AUTOSAR XML (schema 4-2-2)
package /STELLANTIS/EPT/ASWCs
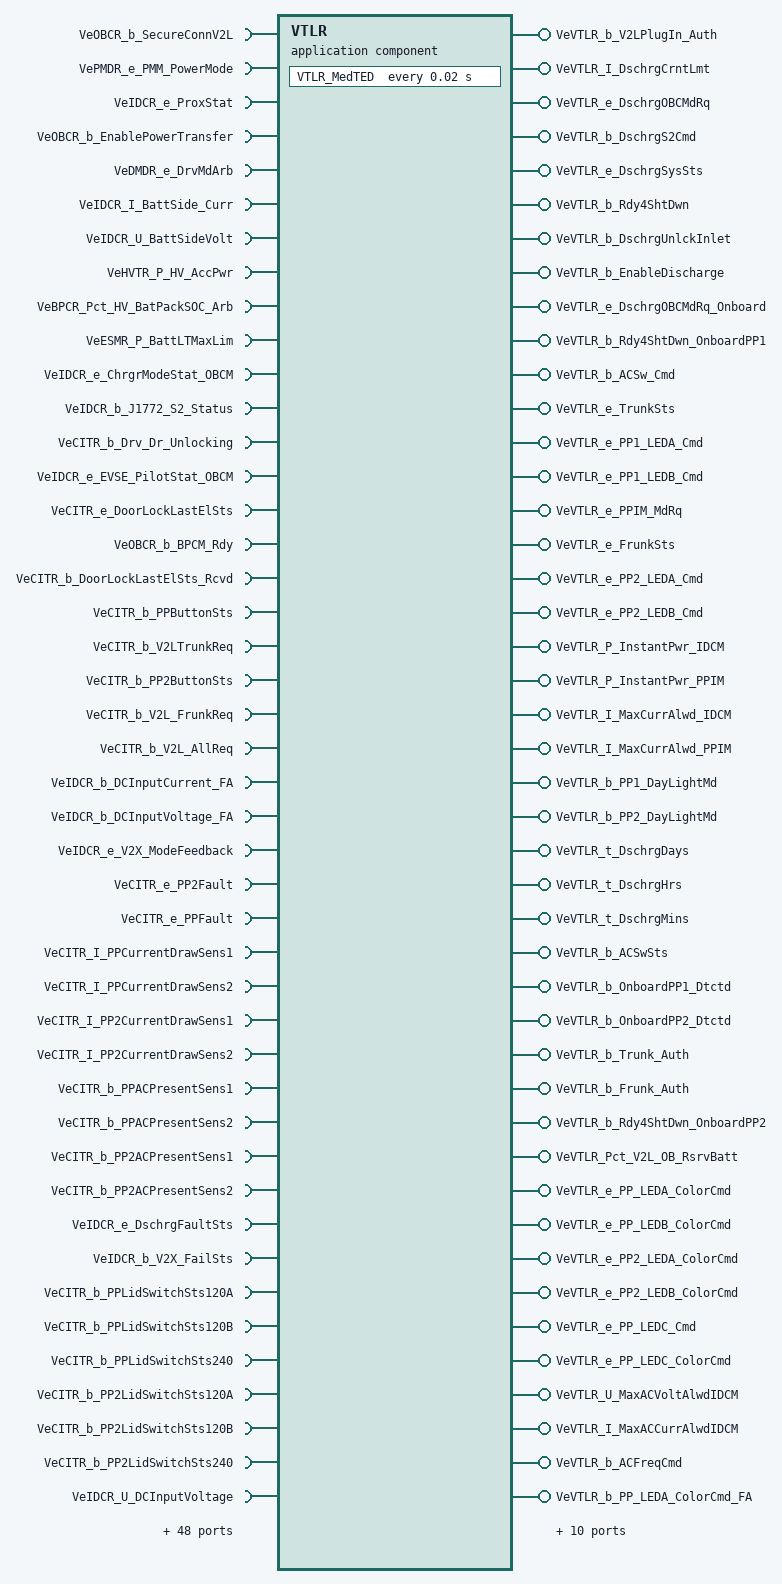
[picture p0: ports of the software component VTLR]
  application sw component type VTLR
    87 x require port:
      VeOBCR_b_SecureConnV2L: variation-point={short-label=vpVeOBCR_b_SecureConnV2L, sw-syscond=1}, nonqueued-receiver-com-spec{data-element=Value, init-value=0}, required-interface=VeOBCR_b_SecureConnV2L
      VePMDR_e_PMM_PowerMode: variation-point={short-label=vpVePMDR_e_PMM_PowerMode, sw-syscond=1}, nonqueued-receiver-com-spec{data-element=Value, init-value=CePMDR_e_PowerMode_Off}, required-interface=VePMDR_e_PMM_PowerMode
      VeIDCR_e_ProxStat: variation-point={short-label=vpVeIDCR_e_ProxStat, sw-syscond=1}, nonqueued-receiver-com-spec{data-element=Value, init-value=CeOBCR_e_ProxLo_OBCM}, required-interface=VeIDCR_e_ProxStat
      VeOBCR_b_EnablePowerTransfer: variation-point={short-label=vpVeOBCR_b_EnablePowerTransfer, sw-syscond=1}, nonqueued-receiver-com-spec{data-element=Value, init-value=0}, required-interface=VeOBCR_b_EnablePowerTransfer
      VeDMDR_e_DrvMdArb: variation-point={short-label=vpVeDMDR_e_DrvMdArb, sw-syscond=1}, nonqueued-receiver-com-spec{data-element=Value, init-value=CeDMDR_e_NoDrvMd}, required-interface=VeDMDR_e_DrvMdArb
      VeIDCR_I_BattSide_Curr: variation-point={short-label=vpVeIDCR_I_BattSide_Curr, sw-syscond=1}, nonqueued-receiver-com-spec{data-element=Value, init-value=0}, required-interface=VeIDCR_I_BattSide_Curr
      VeIDCR_U_BattSideVolt: variation-point={short-label=vpVeIDCR_U_BattSideVolt, sw-syscond=1}, nonqueued-receiver-com-spec{data-element=Value, init-value=0}, required-interface=VeIDCR_U_BattSideVolt
      VeHVTR_P_HV_AccPwr: variation-point={short-label=vpVeHVTR_P_HV_AccPwr, sw-syscond=1}, nonqueued-receiver-com-spec{data-element=Value, init-value=0}, required-interface=VeHVTR_P_HV_AccPwr
      VeBPCR_Pct_HV_BatPackSOC_Arb: variation-point={short-label=vpVeBPCR_Pct_HV_BatPackSOC_Arb, sw-syscond=1}, nonqueued-receiver-com-spec{data-element=Value, init-value=0}, required-interface=VeBPCR_Pct_HV_BatPackSOC_Arb
      VeESMR_P_BattLTMaxLim: variation-point={short-label=vpVeESMR_P_BattLTMaxLim, sw-syscond=1}, nonqueued-receiver-com-spec{data-element=Value, init-value=0}, required-interface=VeESMR_P_BattLTMaxLim
      VeIDCR_e_ChrgrModeStat_OBCM: variation-point={short-label=vpVeIDCR_e_ChrgrModeStat_OBCM, sw-syscond=1}, nonqueued-receiver-com-spec{data-element=Value, init-value=CeOBCR_e_Idle_OBCM}, required-interface=VeIDCR_e_ChrgrModeStat_OBCM
      VeIDCR_b_J1772_S2_Status: variation-point={short-label=vpVeIDCR_b_J1772_S2_Status, sw-syscond=1}, nonqueued-receiver-com-spec{data-element=Value, init-value=0}, required-interface=VeIDCR_b_J1772_S2_Status
      VeCITR_b_Drv_Dr_Unlocking: variation-point={short-label=vpVeCITR_b_Drv_Dr_Unlocking, sw-syscond=1}, nonqueued-receiver-com-spec{data-element=Value, init-value=0}, required-interface=VeCITR_b_Drv_Dr_Unlocking
      VeIDCR_e_EVSE_PilotStat_OBCM: variation-point={short-label=vpVeIDCR_e_EVSE_PilotStat_OBCM, sw-syscond=1}, nonqueued-receiver-com-spec{data-element=Value, init-value=CeOBCR_e_NO_EVSE_OBCM}, required-interface=VeIDCR_e_EVSE_PilotStat_OBCM
      VeCITR_e_DoorLockLastElSts: variation-point={short-label=vpVeCITR_e_DoorLockLastElSts, sw-syscond=1}, nonqueued-receiver-com-spec{data-element=Value, init-value=CeOBCR_e_LKD}, required-interface=VeCITR_e_DoorLockLastElSts
      VeOBCR_b_BPCM_Rdy: variation-point={short-label=vpVeOBCR_b_BPCM_Rdy, sw-syscond=1}, nonqueued-receiver-com-spec{data-element=Value, init-value=0}, required-interface=VeOBCR_b_BPCM_Rdy
      VeCITR_b_DoorLockLastElSts_Rcvd: variation-point={short-label=vpVeCITR_b_DoorLockLastElSts_Rcvd, sw-syscond=1}, nonqueued-receiver-com-spec{data-element=Value, init-value=0}, required-interface=VeCITR_b_DoorLockLastElSts_Rcvd
      VeCITR_b_PPButtonSts: variation-point={short-label=vpVeCITR_b_PPButtonSts, sw-syscond=1}, nonqueued-receiver-com-spec{data-element=Value, init-value=0}, required-interface=VeCITR_b_PPButtonSts
      VeCITR_b_V2LTrunkReq: variation-point={short-label=vpVeCITR_b_V2LTrunkReq, sw-syscond=1}, nonqueued-receiver-com-spec{data-element=Value, init-value=0}, required-interface=VeCITR_b_V2LTrunkReq
      VeCITR_b_PP2ButtonSts: variation-point={short-label=vpVeCITR_b_PP2ButtonSts, sw-syscond=1}, nonqueued-receiver-com-spec{data-element=Value, init-value=0}, required-interface=VeCITR_b_PP2ButtonSts
      VeCITR_b_V2L_FrunkReq: variation-point={short-label=vpVeCITR_b_V2L_FrunkReq, sw-syscond=1}, nonqueued-receiver-com-spec{data-element=Value, init-value=0}, required-interface=VeCITR_b_V2L_FrunkReq
      VeCITR_b_V2L_AllReq: variation-point={short-label=vpVeCITR_b_V2L_AllReq, sw-syscond=1}, nonqueued-receiver-com-spec{data-element=Value, init-value=0}, required-interface=VeCITR_b_V2L_AllReq
      VeIDCR_b_DCInputCurrent_FA: variation-point={short-label=vpVeIDCR_b_DCInputCurrent_FA, sw-syscond=1}, nonqueued-receiver-com-spec{data-element=Value, init-value=0}, required-interface=VeIDCR_b_DCInputCurrent_FA
      VeIDCR_b_DCInputVoltage_FA: variation-point={short-label=vpVeIDCR_b_DCInputVoltage_FA, sw-syscond=1}, nonqueued-receiver-com-spec{data-element=Value, init-value=0}, required-interface=VeIDCR_b_DCInputVoltage_FA
      VeIDCR_e_V2X_ModeFeedback: variation-point={short-label=vpVeIDCR_e_V2X_ModeFeedback, sw-syscond=1}, nonqueued-receiver-com-spec{data-element=Value, init-value=CeIDCR_e_No_Request}, required-interface=VeIDCR_e_V2X_ModeFeedback
      VeCITR_e_PP2Fault: variation-point={short-label=vpVeCITR_e_PP2Fault, sw-syscond=1}, nonqueued-receiver-com-spec{data-element=Value, init-value=CeVTLR_e_NoFaultPP2}, required-interface=VeCITR_e_PP2Fault
      VeCITR_e_PPFault: variation-point={short-label=vpVeCITR_e_PPFault, sw-syscond=1}, nonqueued-receiver-com-spec{data-element=Value, init-value=CeVTLR_e_NoFault}, required-interface=VeCITR_e_PPFault
      VeCITR_I_PPCurrentDrawSens1: variation-point={short-label=vpVeCITR_I_PPCurrentDrawSens1, sw-syscond=1}, nonqueued-receiver-com-spec{data-element=Value, init-value=0}, required-interface=VeCITR_I_PPCurrentDrawSens1
      VeCITR_I_PPCurrentDrawSens2: variation-point={short-label=vpVeCITR_I_PPCurrentDrawSens2, sw-syscond=1}, nonqueued-receiver-com-spec{data-element=Value, init-value=0}, required-interface=VeCITR_I_PPCurrentDrawSens2
      VeCITR_I_PP2CurrentDrawSens1: variation-point={short-label=vpVeCITR_I_PP2CurrentDrawSens1, sw-syscond=1}, nonqueued-receiver-com-spec{data-element=Value, init-value=0}, required-interface=VeCITR_I_PP2CurrentDrawSens1
      VeCITR_I_PP2CurrentDrawSens2: variation-point={short-label=vpVeCITR_I_PP2CurrentDrawSens2, sw-syscond=1}, nonqueued-receiver-com-spec{data-element=Value, init-value=0}, required-interface=VeCITR_I_PP2CurrentDrawSens2
      VeCITR_b_PPACPresentSens1: variation-point={short-label=vpVeCITR_b_PPACPresentSens1, sw-syscond=1}, nonqueued-receiver-com-spec{data-element=Value, init-value=0}, required-interface=VeCITR_b_PPACPresentSens1
      VeCITR_b_PPACPresentSens2: variation-point={short-label=vpVeCITR_b_PPACPresentSens2, sw-syscond=1}, nonqueued-receiver-com-spec{data-element=Value, init-value=0}, required-interface=VeCITR_b_PPACPresentSens2
      VeCITR_b_PP2ACPresentSens1: variation-point={short-label=vpVeCITR_b_PP2ACPresentSens1, sw-syscond=1}, nonqueued-receiver-com-spec{data-element=Value, init-value=0}, required-interface=VeCITR_b_PP2ACPresentSens1
      VeCITR_b_PP2ACPresentSens2: variation-point={short-label=vpVeCITR_b_PP2ACPresentSens2, sw-syscond=1}, nonqueued-receiver-com-spec{data-element=Value, init-value=0}, required-interface=VeCITR_b_PP2ACPresentSens2
      VeIDCR_e_DschrgFaultSts: variation-point={short-label=vpVeIDCR_e_DschrgFaultSts, sw-syscond=1}, nonqueued-receiver-com-spec{data-element=Value, init-value=CeVTLR_e_No_Fault}, required-interface=VeIDCR_e_DschrgFaultSts
      VeIDCR_b_V2X_FailSts: variation-point={short-label=vpVeIDCR_b_V2X_FailSts, sw-syscond=1}, nonqueued-receiver-com-spec{data-element=Value, init-value=0}, required-interface=VeIDCR_b_V2X_FailSts
      VeCITR_b_PPLidSwitchSts120A: variation-point={short-label=vpVeCITR_b_PPLidSwitchSts120A, sw-syscond=1}, nonqueued-receiver-com-spec{data-element=Value, init-value=0}, required-interface=VeCITR_b_PPLidSwitchSts120A
      VeCITR_b_PPLidSwitchSts120B: variation-point={short-label=vpVeCITR_b_PPLidSwitchSts120B, sw-syscond=1}, nonqueued-receiver-com-spec{data-element=Value, init-value=0}, required-interface=VeCITR_b_PPLidSwitchSts120B
      VeCITR_b_PPLidSwitchSts240: variation-point={short-label=vpVeCITR_b_PPLidSwitchSts240, sw-syscond=1}, nonqueued-receiver-com-spec{data-element=Value, init-value=0}, required-interface=VeCITR_b_PPLidSwitchSts240
      VeCITR_b_PP2LidSwitchSts120A: variation-point={short-label=vpVeCITR_b_PP2LidSwitchSts120A, sw-syscond=1}, nonqueued-receiver-com-spec{data-element=Value, init-value=0}, required-interface=VeCITR_b_PP2LidSwitchSts120A
      VeCITR_b_PP2LidSwitchSts120B: variation-point={short-label=vpVeCITR_b_PP2LidSwitchSts120B, sw-syscond=1}, nonqueued-receiver-com-spec{data-element=Value, init-value=0}, required-interface=VeCITR_b_PP2LidSwitchSts120B
      VeCITR_b_PP2LidSwitchSts240: variation-point={short-label=vpVeCITR_b_PP2LidSwitchSts240, sw-syscond=1}, nonqueued-receiver-com-spec{data-element=Value, init-value=0}, required-interface=VeCITR_b_PP2LidSwitchSts240
      VeIDCR_U_DCInputVoltage: variation-point={short-label=vpVeIDCR_U_DCInputVoltage, sw-syscond=1}, nonqueued-receiver-com-spec{data-element=Value, init-value=0}, required-interface=VeIDCR_U_DCInputVoltage
      VeIDCR_b_DschrgFaultSts_FA: variation-point={short-label=vpVeIDCR_b_DschrgFaultSts_FA, sw-syscond=1}, nonqueued-receiver-com-spec{data-element=Value, init-value=0}, required-interface=VeIDCR_b_DschrgFaultSts_FA
      VeIDCR_b_V2X_InputCurrent_FA: variation-point={short-label=vpVeIDCR_b_V2X_InputCurrent_FA, sw-syscond=1}, nonqueued-receiver-com-spec{data-element=Value, init-value=0}, required-interface=VeIDCR_b_V2X_InputCurrent_FA
      VeIDCR_b_V2X_InputVoltage_FA: variation-point={short-label=vpVeIDCR_b_V2X_InputVoltage_FA, sw-syscond=1}, nonqueued-receiver-com-spec{data-element=Value, init-value=0}, required-interface=VeIDCR_b_V2X_InputVoltage_FA
      VeIDCR_b_V2X_FailSts_FA: variation-point={short-label=vpVeIDCR_b_V2X_FailSts_FA, sw-syscond=1}, nonqueued-receiver-com-spec{data-element=Value, init-value=0}, required-interface=VeIDCR_b_V2X_FailSts_FA
      VeCITR_P_PPRatedPower: variation-point={short-label=vpVeCITR_P_PPRatedPower, sw-syscond=1}, nonqueued-receiver-com-spec{data-element=Value, init-value=0}, required-interface=VeCITR_P_PPRatedPower
      VeCITR_P_PP2RatedPower: variation-point={short-label=vpVeCITR_P_PP2RatedPower, sw-syscond=1}, nonqueued-receiver-com-spec{data-element=Value, init-value=0}, required-interface=VeCITR_P_PP2RatedPower
      VeIDCR_U_V2X_InputVoltage: variation-point={short-label=vpVeIDCR_U_V2X_InputVoltage, sw-syscond=1}, nonqueued-receiver-com-spec{data-element=Value, init-value=0}, required-interface=VeIDCR_U_V2X_InputVoltage
      VePLTR_t_RTC_CurrentTime: variation-point={short-label=vpVePLTR_t_RTC_CurrentTime, sw-syscond=1}, nonqueued-receiver-com-spec{data-element=Value, init-value=0}, required-interface=VePLTR_t_RTC_CurrentTime
      VeIDCR_I_ACOutCurrent1: variation-point={short-label=vpVeIDCR_I_ACOutCurrent1, sw-syscond=1}, nonqueued-receiver-com-spec{data-element=Value, init-value=0}, required-interface=VeIDCR_I_ACOutCurrent1
      VeIDCR_U_ACOutVoltage1: variation-point={short-label=vpVeIDCR_U_ACOutVoltage1, sw-syscond=1}, nonqueued-receiver-com-spec{data-element=Value, init-value=0}, required-interface=VeIDCR_U_ACOutVoltage1
      VeIDCR_I_ACOutCurrent2: variation-point={short-label=vpVeIDCR_I_ACOutCurrent2, sw-syscond=1}, nonqueued-receiver-com-spec{data-element=Value, init-value=0}, required-interface=VeIDCR_I_ACOutCurrent2
      VeIDCR_U_ACOutVoltage2: variation-point={short-label=vpVeIDCR_U_ACOutVoltage2, sw-syscond=1}, nonqueued-receiver-com-spec{data-element=Value, init-value=0}, required-interface=VeIDCR_U_ACOutVoltage2
      VeIDCR_I_AcOutCurrent: variation-point={short-label=vpVeIDCR_I_AcOutCurrent, sw-syscond=1}, nonqueued-receiver-com-spec{data-element=Value, init-value=0}, required-interface=VeIDCR_I_AcOutCurrent
      VeIDCR_U_AcOutVoltage: variation-point={short-label=vpVeIDCR_U_AcOutVoltage, sw-syscond=1}, nonqueued-receiver-com-spec{data-element=Value, init-value=0}, required-interface=VeIDCR_U_AcOutVoltage
      VeERER_E_WhRemaining_V2L: variation-point={short-label=vpVeERER_E_WhRemaining_V2L, sw-syscond=1}, nonqueued-receiver-com-spec{data-element=Value, init-value=0}, required-interface=VeERER_E_WhRemaining_V2L
      VeVTXR_e_PowerPanelMd: variation-point={short-label=vpVeVTXR_e_PowerPanelMd, sw-syscond=1}, nonqueued-receiver-com-spec{data-element=Value, init-value=CeVTXR_e_DefaultMd}, required-interface=VeVTXR_e_PowerPanelMd
      VeHPMR_b_PropSysActv: variation-point={short-label=vpVeHPMR_b_PropSysActv, sw-syscond=1}, nonqueued-receiver-com-spec{data-element=Value, init-value=0}, required-interface=VeHPMR_b_PropSysActv
      VeCITR_b_V2LSubmit: variation-point={short-label=vpVeCITR_b_V2LSubmit, sw-syscond=1}, nonqueued-receiver-com-spec{data-element=Value, init-value=0}, required-interface=VeCITR_b_V2LSubmit
      VeVDVR_e_DschrgSysSts: variation-point={short-label=vpVeVDVR_e_DschrgSysSts, sw-syscond=1}, nonqueued-receiver-com-spec{data-element=Value, init-value=CeVTLR_e_DschrgInactv}, required-interface=VeVDVR_e_DschrgSysSts
      VeVDVR_I_DschrgCrntLmt: variation-point={short-label=vpVeVDVR_I_DschrgCrntLmt, sw-syscond=1}, nonqueued-receiver-com-spec{data-element=Value, init-value=0}, required-interface=VeVDVR_I_DschrgCrntLmt
      VeSSDR_b_DsblHVBattDischrg: variation-point={short-label=vpVeSSDR_b_DsblHVBattDischrg, sw-syscond=1}, nonqueued-receiver-com-spec{data-element=Value, init-value=0}, required-interface=VeSSDR_b_DsblHVBattDischrg
      VeSRAR_b_StpCharging: variation-point={short-label=vpVeSRAR_b_StpCharging, sw-syscond=1}, nonqueued-receiver-com-spec{data-element=Value, init-value=0}, required-interface=VeSRAR_b_StpCharging
      VeGENR_b_LV_SysVoltage_Low: variation-point={short-label=vpVeGENR_b_LV_SysVoltage_Low, sw-syscond=1}, nonqueued-receiver-com-spec{data-element=Value, init-value=0}, required-interface=VeGENR_b_LV_SysVoltage_Low
      VeCITR_e_FOTA_Install_Type: variation-point={short-label=vpVeCITR_e_FOTA_Install_Type, sw-syscond=1}, nonqueued-receiver-com-spec{data-element=Value, init-value=CeCITR_e_NoFOTA}, required-interface=VeCITR_e_FOTA_Install_Type
      VeCITR_e_FOTA_Install_Status: variation-point={short-label=vpVeCITR_e_FOTA_Install_Status, sw-syscond=1}, nonqueued-receiver-com-spec{data-element=Value, init-value=CeCITR_e_Installation_Default}, required-interface=VeCITR_e_FOTA_Install_Status
      VeFSCR_b_HVFuncRejHdAjar: variation-point={short-label=vpVeFSCR_b_HVFuncRejHdAjar, sw-syscond=1}, nonqueued-receiver-com-spec{data-element=Value, init-value=0}, required-interface=VeFSCR_b_HVFuncRejHdAjar
      VeBPCR_e_HV_BatCntctrStat: variation-point={short-label=vpVeBPCR_e_HV_BatCntctrStat, sw-syscond=1}, nonqueued-receiver-com-spec{data-element=Value, init-value=CeHVTR_e_Open}, required-interface=VeBPCR_e_HV_BatCntctrStat
      VeCSVR_v_VehSpdSigned: variation-point={short-label=vpVeCSVR_v_VehSpdSigned, sw-syscond=1}, nonqueued-receiver-com-spec{data-element=Value, init-value=0}, required-interface=VeCSVR_v_VehSpdSigned
      VeCSVR_b_VehSpdFA: variation-point={short-label=vpVeCSVR_b_VehSpdFA, sw-syscond=1}, nonqueued-receiver-com-spec{data-element=Value, init-value=0}, required-interface=VeCSVR_b_VehSpdFA
      VeHPMR_b_BattCntctrOpenPndg: variation-point={short-label=vpVeHPMR_b_BattCntctrOpenPndg, sw-syscond=1}, nonqueued-receiver-com-spec{data-element=Value, init-value=0}, required-interface=VeHPMR_b_BattCntctrOpenPndg
      VePLTR_b_RmtVehStartReq: variation-point={short-label=vpVePLTR_b_RmtVehStartReq, sw-syscond=1}, nonqueued-receiver-com-spec{data-element=Value, init-value=0}, required-interface=VePLTR_b_RmtVehStartReq
      VeOBCR_b_PluggedIn: variation-point={short-label=vpVeOBCR_b_PluggedIn, sw-syscond=1}, nonqueued-receiver-com-spec{data-element=Value, init-value=0}, required-interface=VeOBCR_b_PluggedIn
      VePLTR_b_InternalLightSts: variation-point={short-label=vpVePLTR_b_InternalLightSts, sw-syscond=1}, nonqueued-receiver-com-spec{data-element=Value, init-value=0}, required-interface=VePLTR_b_InternalLightSts
      VeDMDR_e_TurtleMdSts: variation-point={short-label=vpVeDMDR_e_TurtleMdSts, sw-syscond=1}, nonqueued-receiver-com-spec{data-element=Value, init-value=CeDMDR_e_No_Turtle_Mode}, required-interface=VeDMDR_e_TurtleMdSts
      VeHPMR_b_CntrlrPwrHold: variation-point={short-label=vpVeHPMR_b_CntrlrPwrHold, sw-syscond=1}, nonqueued-receiver-com-spec{data-element=Value, init-value=0}, required-interface=VeHPMR_b_CntrlrPwrHold
      VeTRGR_e_VldtdTransRngSt: variation-point={short-label=vpVeTRGR_e_VldtdTransRngSt, sw-syscond=1}, nonqueued-receiver-com-spec{data-element=Value, init-value=CeTRGR_e_NoSelectionAvailable}, required-interface=VeTRGR_e_VldtdTransRngSt
      VePRXR_e_OnboardPowPanelType: variation-point={short-label=vpVePRXR_e_OnboardPowPanelType, sw-syscond=1}, nonqueued-receiver-com-spec{data-element=Value, init-value=CePRXR_e_NoType}, required-interface=VePRXR_e_OnboardPowPanelType
      VePRXR_b_V2L_Present: variation-point={short-label=vpVePRXR_b_V2L_Present, sw-syscond=1}, nonqueued-receiver-com-spec{data-element=Value, init-value=0}, required-interface=VePRXR_b_V2L_Present
      VeCITR_b_PP_Gnd_Fault_Detected: variation-point={short-label=vpVeCITR_b_PP_Gnd_Fault_Detected, sw-syscond=1}, nonqueued-receiver-com-spec{data-element=Value, init-value=0}, required-interface=VeCITR_b_PP_Gnd_Fault_Detected
      VeCITR_b_PP2_Gnd_Fault_Detected: variation-point={short-label=vpVeCITR_b_PP2_Gnd_Fault_Detected, sw-syscond=1}, nonqueued-receiver-com-spec{data-element=Value, init-value=0}, required-interface=VeCITR_b_PP2_Gnd_Fault_Detected
      VeIDCR_b_IDCM_GFCI_Fault_Status: variation-point={short-label=vpVeIDCR_b_IDCM_GFCI_Fault_Status, sw-syscond=1}, nonqueued-receiver-com-spec{data-element=Value, init-value=0}, required-interface=VeIDCR_b_IDCM_GFCI_Fault_Status
      VeIDCR_I_DCInputCurrent: variation-point={short-label=vpVeIDCR_I_DCInputCurrent, sw-syscond=1}, nonqueued-receiver-com-spec{data-element=Value, init-value=0}, required-interface=VeIDCR_I_DCInputCurrent
      VeIDCR_I_V2X_InputCurrent: variation-point={short-label=vpVeIDCR_I_V2X_InputCurrent, sw-syscond=1}, nonqueued-receiver-com-spec{data-element=Value, init-value=0}, required-interface=VeIDCR_I_V2X_InputCurrent
    49 x provide port:
      VeVTLR_b_V2LPlugIn_Auth: nonqueued-sender-com-spec{data-element=Value, init-value=0}, provided-interface=VeVTLR_b_V2LPlugIn_Auth
      VeVTLR_I_DschrgCrntLmt: nonqueued-sender-com-spec{data-element=Value, init-value=0}, provided-interface=VeVTLR_I_DschrgCrntLmt
      VeVTLR_e_DschrgOBCMdRq: nonqueued-sender-com-spec{data-element=Value, init-value=CeOBCR_e_Idle_OBCMdRq}, provided-interface=VeVTLR_e_DschrgOBCMdRq
      VeVTLR_b_DschrgS2Cmd: nonqueued-sender-com-spec{data-element=Value, init-value=0}, provided-interface=VeVTLR_b_DschrgS2Cmd
      VeVTLR_e_DschrgSysSts: nonqueued-sender-com-spec{data-element=Value, init-value=CeVTLR_e_DschrgInactv}, provided-interface=VeVTLR_e_DschrgSysSts
      VeVTLR_b_Rdy4ShtDwn: nonqueued-sender-com-spec{data-element=Value, init-value=0}, provided-interface=VeVTLR_b_Rdy4ShtDwn
      VeVTLR_b_DschrgUnlckInlet: nonqueued-sender-com-spec{data-element=Value, init-value=0}, provided-interface=VeVTLR_b_DschrgUnlckInlet
      VeVTLR_b_EnableDischarge: nonqueued-sender-com-spec{data-element=Value, init-value=0}, provided-interface=VeVTLR_b_EnableDischarge
      VeVTLR_e_DschrgOBCMdRq_Onboard: nonqueued-sender-com-spec{data-element=Value, init-value=CeOBCR_e_Idle_OBCMdRq}, provided-interface=VeVTLR_e_DschrgOBCMdRq_Onboard
      VeVTLR_b_Rdy4ShtDwn_OnboardPP1: nonqueued-sender-com-spec{data-element=Value, init-value=0}, provided-interface=VeVTLR_b_Rdy4ShtDwn_OnboardPP1
      VeVTLR_b_ACSw_Cmd: nonqueued-sender-com-spec{data-element=Value, init-value=0}, provided-interface=VeVTLR_b_ACSw_Cmd
      VeVTLR_e_TrunkSts: nonqueued-sender-com-spec{data-element=Value, init-value=CeVTLR_e_Inactive}, provided-interface=VeVTLR_e_TrunkSts
      VeVTLR_e_PP1_LEDA_Cmd: nonqueued-sender-com-spec{data-element=Value, init-value=CeVTLR_e_Led_Off}, provided-interface=VeVTLR_e_PP1_LEDA_Cmd
      VeVTLR_e_PP1_LEDB_Cmd: nonqueued-sender-com-spec{data-element=Value, init-value=CeVTLR_e_Led_Off}, provided-interface=VeVTLR_e_PP1_LEDB_Cmd
      VeVTLR_e_PPIM_MdRq: nonqueued-sender-com-spec{data-element=Value, init-value=CeVTLR_e_Idle}, provided-interface=VeVTLR_e_PPIM_MdRq
      VeVTLR_e_FrunkSts: nonqueued-sender-com-spec{data-element=Value, init-value=CeVTLR_e_Inactive_Frunk}, provided-interface=VeVTLR_e_FrunkSts
      VeVTLR_e_PP2_LEDA_Cmd: nonqueued-sender-com-spec{data-element=Value, init-value=CeVTLR_e_Led_Off}, provided-interface=VeVTLR_e_PP2_LEDA_Cmd
      VeVTLR_e_PP2_LEDB_Cmd: nonqueued-sender-com-spec{data-element=Value, init-value=CeVTLR_e_Led_Off}, provided-interface=VeVTLR_e_PP2_LEDB_Cmd
      VeVTLR_P_InstantPwr_IDCM: nonqueued-sender-com-spec{data-element=Value, init-value=0}, provided-interface=VeVTLR_P_InstantPwr_IDCM
      VeVTLR_P_InstantPwr_PPIM: nonqueued-sender-com-spec{data-element=Value, init-value=0}, provided-interface=VeVTLR_P_InstantPwr_PPIM
      VeVTLR_I_MaxCurrAlwd_IDCM: nonqueued-sender-com-spec{data-element=Value, init-value=0}, provided-interface=VeVTLR_I_MaxCurrAlwd_IDCM
      VeVTLR_I_MaxCurrAlwd_PPIM: nonqueued-sender-com-spec{data-element=Value, init-value=0}, provided-interface=VeVTLR_I_MaxCurrAlwd_PPIM
      VeVTLR_b_PP1_DayLightMd: nonqueued-sender-com-spec{data-element=Value, init-value=0}, provided-interface=VeVTLR_b_PP1_DayLightMd
      VeVTLR_b_PP2_DayLightMd: nonqueued-sender-com-spec{data-element=Value, init-value=0}, provided-interface=VeVTLR_b_PP2_DayLightMd
      VeVTLR_t_DschrgDays: nonqueued-sender-com-spec{data-element=Value, init-value=0}, provided-interface=VeVTLR_t_DschrgDays
      VeVTLR_t_DschrgHrs: nonqueued-sender-com-spec{data-element=Value, init-value=0}, provided-interface=VeVTLR_t_DschrgHrs
      VeVTLR_t_DschrgMins: nonqueued-sender-com-spec{data-element=Value, init-value=0}, provided-interface=VeVTLR_t_DschrgMins
      VeVTLR_b_ACSwSts: nonqueued-sender-com-spec{data-element=Value, init-value=0}, provided-interface=VeVTLR_b_ACSwSts
      VeVTLR_b_OnboardPP1_Dtctd: nonqueued-sender-com-spec{data-element=Value, init-value=0}, provided-interface=VeVTLR_b_OnboardPP1_Dtctd
      VeVTLR_b_OnboardPP2_Dtctd: nonqueued-sender-com-spec{data-element=Value, init-value=0}, provided-interface=VeVTLR_b_OnboardPP2_Dtctd
      VeVTLR_b_Trunk_Auth: nonqueued-sender-com-spec{data-element=Value, init-value=0}, provided-interface=VeVTLR_b_Trunk_Auth
      VeVTLR_b_Frunk_Auth: nonqueued-sender-com-spec{data-element=Value, init-value=0}, provided-interface=VeVTLR_b_Frunk_Auth
      VeVTLR_b_Rdy4ShtDwn_OnboardPP2: nonqueued-sender-com-spec{data-element=Value, init-value=0}, provided-interface=VeVTLR_b_Rdy4ShtDwn_OnboardPP2
      VeVTLR_Pct_V2L_OB_RsrvBatt: nonqueued-sender-com-spec{data-element=Value, init-value=0}, provided-interface=VeVTLR_Pct_V2L_OB_RsrvBatt
      VeVTLR_e_PP_LEDA_ColorCmd: nonqueued-sender-com-spec{data-element=Value, init-value=CeVTLR_e_Init}, provided-interface=VeVTLR_e_PP_LEDA_ColorCmd
      VeVTLR_e_PP_LEDB_ColorCmd: nonqueued-sender-com-spec{data-element=Value, init-value=CeVTLR_e_Init}, provided-interface=VeVTLR_e_PP_LEDB_ColorCmd
      VeVTLR_e_PP2_LEDA_ColorCmd: nonqueued-sender-com-spec{data-element=Value, init-value=CeVTLR_e_Init}, provided-interface=VeVTLR_e_PP2_LEDA_ColorCmd
      VeVTLR_e_PP2_LEDB_ColorCmd: nonqueued-sender-com-spec{data-element=Value, init-value=CeVTLR_e_Init}, provided-interface=VeVTLR_e_PP2_LEDB_ColorCmd
      VeVTLR_e_PP_LEDC_Cmd: nonqueued-sender-com-spec{data-element=Value, init-value=CeVTLR_e_Led_Off}, provided-interface=VeVTLR_e_PP_LEDC_Cmd
      VeVTLR_e_PP_LEDC_ColorCmd: nonqueued-sender-com-spec{data-element=Value, init-value=CeVTLR_e_Init}, provided-interface=VeVTLR_e_PP_LEDC_ColorCmd
      VeVTLR_U_MaxACVoltAlwdIDCM: nonqueued-sender-com-spec{data-element=Value, init-value=0}, provided-interface=VeVTLR_U_MaxACVoltAlwdIDCM
      VeVTLR_I_MaxACCurrAlwdIDCM: nonqueued-sender-com-spec{data-element=Value, init-value=0}, provided-interface=VeVTLR_I_MaxACCurrAlwdIDCM
      VeVTLR_b_ACFreqCmd: nonqueued-sender-com-spec{data-element=Value, init-value=0}, provided-interface=VeVTLR_b_ACFreqCmd
      VeVTLR_b_PP_LEDA_ColorCmd_FA: nonqueued-sender-com-spec{data-element=Value, init-value=0}, provided-interface=VeVTLR_b_PP_LEDA_ColorCmd_FA
      VeVTLR_b_PP_LEDB_ColorCmd_FA: nonqueued-sender-com-spec{data-element=Value, init-value=0}, provided-interface=VeVTLR_b_PP_LEDB_ColorCmd_FA
      VeVTLR_b_PP_LEDC_ColorCmd_FA: nonqueued-sender-com-spec{data-element=Value, init-value=0}, provided-interface=VeVTLR_b_PP_LEDC_ColorCmd_FA
      VeVTLR_b_PP2_LEDA_ColorCmd_FA: nonqueued-sender-com-spec{data-element=Value, init-value=0}, provided-interface=VeVTLR_b_PP2_LEDA_ColorCmd_FA
      VeVTLR_b_PP2_LEDB_ColorCmd_FA: nonqueued-sender-com-spec{data-element=Value, init-value=0}, provided-interface=VeVTLR_b_PP2_LEDB_ColorCmd_FA
      VeVTLR_b_PP_LEDC_Cmd_FA: nonqueued-sender-com-spec{data-element=Value, init-value=0}, provided-interface=VeVTLR_b_PP_LEDC_Cmd_FA
    5 x require port:
      EeVTLR_b_V2L_PlugInAuth_Rx: variation-point={short-label=vpEeVTLR_b_V2L_PlugInAuth_Rx, sw-syscond=1}, nv-require-com-spec{init-value=0, variable=EeVTLR_b_V2L_PlugInAuth}, required-interface=EeVTLR_b_V2L_PlugInAuth
      EeVTLR_Cnt_AuthTmr_Rx: variation-point={short-label=vpEeVTLR_Cnt_AuthTmr_Rx, sw-syscond=1}, nv-require-com-spec{init-value=0, variable=EeVTLR_Cnt_AuthTmr}, required-interface=EeVTLR_Cnt_AuthTmr
      NeVTLR_e_DoorLastSts_Rx: variation-point={short-label=vpNeVTLR_e_DoorLastSts_Rx, sw-syscond=1}, nv-require-com-spec{init-value=CeOBCR_e_LKD, variable=NeVTLR_e_DoorLastSts}, required-interface=NeVTLR_e_DoorLastSts
      EeVTLR_b_V2L_OB_IDCM_Auth_Rx: variation-point={short-label=vpEeVTLR_b_V2L_OB_IDCM_Auth_Rx, sw-syscond=1}, nv-require-com-spec{init-value=0, variable=EeVTLR_b_V2L_OB_IDCM_Auth}, required-interface=EeVTLR_b_V2L_OB_IDCM_Auth
      EeVTLR_b_V2L_OB_PPIM_Auth_Rx: variation-point={short-label=vpEeVTLR_b_V2L_OB_PPIM_Auth_Rx, sw-syscond=1}, nv-require-com-spec{init-value=0, variable=EeVTLR_b_V2L_OB_PPIM_Auth}, required-interface=EeVTLR_b_V2L_OB_PPIM_Auth
    5 x provide port:
      EeVTLR_b_V2L_PlugInAuth: variation-point={short-label=vpEeVTLR_b_V2L_PlugInAuth, sw-syscond=1}, nv-provide-com-spec{ram-block-init-value=0, variable=EeVTLR_b_V2L_PlugInAuth}, provided-interface=EeVTLR_b_V2L_PlugInAuth
      EeVTLR_Cnt_AuthTmr: variation-point={short-label=vpEeVTLR_Cnt_AuthTmr, sw-syscond=1}, nv-provide-com-spec{ram-block-init-value=0, variable=EeVTLR_Cnt_AuthTmr}, provided-interface=EeVTLR_Cnt_AuthTmr
      NeVTLR_e_DoorLastSts: variation-point={short-label=vpNeVTLR_e_DoorLastSts, sw-syscond=1}, nv-provide-com-spec{ram-block-init-value=CeOBCR_e_LKD, variable=NeVTLR_e_DoorLastSts}, provided-interface=NeVTLR_e_DoorLastSts
      EeVTLR_b_V2L_OB_IDCM_Auth: variation-point={short-label=vpEeVTLR_b_V2L_OB_IDCM_Auth, sw-syscond=1}, nv-provide-com-spec{ram-block-init-value=0, variable=EeVTLR_b_V2L_OB_IDCM_Auth}, provided-interface=EeVTLR_b_V2L_OB_IDCM_Auth
      EeVTLR_b_V2L_OB_PPIM_Auth: variation-point={short-label=vpEeVTLR_b_V2L_OB_PPIM_Auth, sw-syscond=1}, nv-provide-com-spec{ram-block-init-value=0, variable=EeVTLR_b_V2L_OB_PPIM_Auth}, provided-interface=EeVTLR_b_V2L_OB_PPIM_Auth
    behavior IB_VTLR: data-type-mapping=msADTtoIDTMapping, handle-termination-and-restart=NO-SUPPORT, included-data-type-set=data-type=TeVTLR_e_DischrgSt
      timing event Event_MedTED: start-on-event=VTLR_MedTED, period=0.02
      init event Event_VTLR_ac_Init: start-on-event=VTLR_ac_Init
      init event Event_PwrOn: start-on-event=VTLR_PwrOn
      init event Event_PwrOff: start-on-event=VTLR_PwrOff
      4 x runnable:
        VTLR_ac_Init
          data-send-points:
            16 x access:
              OUT_VeVTLR_e_DschrgOBCMdRq_Value: accessed-variable=VeVTLR_e_DschrgOBCMdRq.Value
              OUT_VeVTLR_e_DschrgSysSts_Value: accessed-variable=VeVTLR_e_DschrgSysSts.Value
              OUT_VeVTLR_e_DschrgOBCMdRq_Onboard_Value: accessed-variable=VeVTLR_e_DschrgOBCMdRq_Onboard.Value
              OUT_VeVTLR_e_TrunkSts_Value: accessed-variable=VeVTLR_e_TrunkSts.Value
              OUT_VeVTLR_e_PP1_LEDA_Cmd_Value: accessed-variable=VeVTLR_e_PP1_LEDA_Cmd.Value
              OUT_VeVTLR_e_PP1_LEDB_Cmd_Value: accessed-variable=VeVTLR_e_PP1_LEDB_Cmd.Value
              OUT_VeVTLR_e_PPIM_MdRq_Value: accessed-variable=VeVTLR_e_PPIM_MdRq.Value
              OUT_VeVTLR_e_FrunkSts_Value: accessed-variable=VeVTLR_e_FrunkSts.Value
              OUT_VeVTLR_e_PP2_LEDA_Cmd_Value: accessed-variable=VeVTLR_e_PP2_LEDA_Cmd.Value
              OUT_VeVTLR_e_PP2_LEDB_Cmd_Value: accessed-variable=VeVTLR_e_PP2_LEDB_Cmd.Value
              OUT_VeVTLR_e_PP_LEDA_ColorCmd_Value: accessed-variable=VeVTLR_e_PP_LEDA_ColorCmd.Value
              OUT_VeVTLR_e_PP_LEDB_ColorCmd_Value: accessed-variable=VeVTLR_e_PP_LEDB_ColorCmd.Value
              OUT_VeVTLR_e_PP2_LEDA_ColorCmd_Value: accessed-variable=VeVTLR_e_PP2_LEDA_ColorCmd.Value
              OUT_VeVTLR_e_PP2_LEDB_ColorCmd_Value: accessed-variable=VeVTLR_e_PP2_LEDB_ColorCmd.Value
              OUT_VeVTLR_e_PP_LEDC_Cmd_Value: accessed-variable=VeVTLR_e_PP_LEDC_Cmd.Value
              OUT_VeVTLR_e_PP_LEDC_ColorCmd_Value: accessed-variable=VeVTLR_e_PP_LEDC_ColorCmd.Value
        VTLR_PwrOn
          data-receive-point-by-arguments:
            5 x access:
              IN_EeVTLR_Cnt_AuthTmr_Rx_EeVTLR_Cnt_AuthTmr: accessed-variable=EeVTLR_Cnt_AuthTmr_Rx.EeVTLR_Cnt_AuthTmr, variation-point={short-label=vpIN_EeVTLR_Cnt_AuthTmr_Rx_EeVTLR_Cnt_AuthTmr, sw-syscond=1}
              IN_EeVTLR_b_V2L_OB_IDCM_Auth_Rx_EeVTLR_b_V2L_OB_IDCM_Auth: accessed-variable=EeVTLR_b_V2L_OB_IDCM_Auth_Rx.EeVTLR_b_V2L_OB_IDCM_Auth, variation-point={short-label=vpIN_EeVTLR_b_V2L_OB_IDCM_Auth_Rx_EeVTLR_b_V2L_OB_IDCM_Auth, sw-syscond=1}
              IN_EeVTLR_b_V2L_OB_PPIM_Auth_Rx_EeVTLR_b_V2L_OB_PPIM_Auth: accessed-variable=EeVTLR_b_V2L_OB_PPIM_Auth_Rx.EeVTLR_b_V2L_OB_PPIM_Auth, variation-point={short-label=vpIN_EeVTLR_b_V2L_OB_PPIM_Auth_Rx_EeVTLR_b_V2L_OB_PPIM_Auth, sw-syscond=1}
              IN_EeVTLR_b_V2L_PlugInAuth_Rx_EeVTLR_b_V2L_PlugInAuth: accessed-variable=EeVTLR_b_V2L_PlugInAuth_Rx.EeVTLR_b_V2L_PlugInAuth, variation-point={short-label=vpIN_EeVTLR_b_V2L_PlugInAuth_Rx_EeVTLR_b_V2L_PlugInAuth, sw-syscond=1}
              IN_NeVTLR_e_DoorLastSts_Rx_NeVTLR_e_DoorLastSts: accessed-variable=NeVTLR_e_DoorLastSts_Rx.NeVTLR_e_DoorLastSts, variation-point={short-label=vpIN_NeVTLR_e_DoorLastSts_Rx_NeVTLR_e_DoorLastSts, sw-syscond=1}
          data-send-points:
            49 x access:
              OUT_VeVTLR_b_V2LPlugIn_Auth_Value: accessed-variable=VeVTLR_b_V2LPlugIn_Auth.Value
              OUT_VeVTLR_I_DschrgCrntLmt_Value: accessed-variable=VeVTLR_I_DschrgCrntLmt.Value
              OUT_VeVTLR_e_DschrgOBCMdRq_Value: accessed-variable=VeVTLR_e_DschrgOBCMdRq.Value
              OUT_VeVTLR_b_DschrgS2Cmd_Value: accessed-variable=VeVTLR_b_DschrgS2Cmd.Value
              OUT_VeVTLR_e_DschrgSysSts_Value: accessed-variable=VeVTLR_e_DschrgSysSts.Value
              OUT_VeVTLR_b_Rdy4ShtDwn_Value: accessed-variable=VeVTLR_b_Rdy4ShtDwn.Value
              OUT_VeVTLR_b_DschrgUnlckInlet_Value: accessed-variable=VeVTLR_b_DschrgUnlckInlet.Value
              OUT_VeVTLR_b_EnableDischarge_Value: accessed-variable=VeVTLR_b_EnableDischarge.Value
              OUT_VeVTLR_e_DschrgOBCMdRq_Onboard_Value: accessed-variable=VeVTLR_e_DschrgOBCMdRq_Onboard.Value
              OUT_VeVTLR_b_Rdy4ShtDwn_OnboardPP1_Value: accessed-variable=VeVTLR_b_Rdy4ShtDwn_OnboardPP1.Value
              OUT_VeVTLR_b_Rdy4ShtDwn_OnboardPP2_Value: accessed-variable=VeVTLR_b_Rdy4ShtDwn_OnboardPP2.Value
              OUT_VeVTLR_b_ACSw_Cmd_Value: accessed-variable=VeVTLR_b_ACSw_Cmd.Value
              OUT_VeVTLR_e_TrunkSts_Value: accessed-variable=VeVTLR_e_TrunkSts.Value
              OUT_VeVTLR_e_PP1_LEDA_Cmd_Value: accessed-variable=VeVTLR_e_PP1_LEDA_Cmd.Value
              OUT_VeVTLR_e_PP1_LEDB_Cmd_Value: accessed-variable=VeVTLR_e_PP1_LEDB_Cmd.Value
              OUT_VeVTLR_e_PPIM_MdRq_Value: accessed-variable=VeVTLR_e_PPIM_MdRq.Value
              OUT_VeVTLR_e_FrunkSts_Value: accessed-variable=VeVTLR_e_FrunkSts.Value
              OUT_VeVTLR_e_PP2_LEDA_Cmd_Value: accessed-variable=VeVTLR_e_PP2_LEDA_Cmd.Value
              OUT_VeVTLR_e_PP2_LEDB_Cmd_Value: accessed-variable=VeVTLR_e_PP2_LEDB_Cmd.Value
              OUT_VeVTLR_P_InstantPwr_IDCM_Value: accessed-variable=VeVTLR_P_InstantPwr_IDCM.Value
              OUT_VeVTLR_P_InstantPwr_PPIM_Value: accessed-variable=VeVTLR_P_InstantPwr_PPIM.Value
              OUT_VeVTLR_I_MaxCurrAlwd_IDCM_Value: accessed-variable=VeVTLR_I_MaxCurrAlwd_IDCM.Value
              OUT_VeVTLR_I_MaxCurrAlwd_PPIM_Value: accessed-variable=VeVTLR_I_MaxCurrAlwd_PPIM.Value
              OUT_VeVTLR_b_PP1_DayLightMd_Value: accessed-variable=VeVTLR_b_PP1_DayLightMd.Value
              OUT_VeVTLR_b_PP2_DayLightMd_Value: accessed-variable=VeVTLR_b_PP2_DayLightMd.Value
              OUT_VeVTLR_t_DschrgDays_Value: accessed-variable=VeVTLR_t_DschrgDays.Value
              OUT_VeVTLR_t_DschrgHrs_Value: accessed-variable=VeVTLR_t_DschrgHrs.Value
              OUT_VeVTLR_t_DschrgMins_Value: accessed-variable=VeVTLR_t_DschrgMins.Value
              OUT_VeVTLR_b_ACSwSts_Value: accessed-variable=VeVTLR_b_ACSwSts.Value
              OUT_VeVTLR_b_OnboardPP1_Dtctd_Value: accessed-variable=VeVTLR_b_OnboardPP1_Dtctd.Value
              OUT_VeVTLR_b_OnboardPP2_Dtctd_Value: accessed-variable=VeVTLR_b_OnboardPP2_Dtctd.Value
              OUT_VeVTLR_b_Trunk_Auth_Value: accessed-variable=VeVTLR_b_Trunk_Auth.Value
              OUT_VeVTLR_b_Frunk_Auth_Value: accessed-variable=VeVTLR_b_Frunk_Auth.Value
              OUT_VeVTLR_Pct_V2L_OB_RsrvBatt_Value: accessed-variable=VeVTLR_Pct_V2L_OB_RsrvBatt.Value
              OUT_VeVTLR_e_PP_LEDA_ColorCmd_Value: accessed-variable=VeVTLR_e_PP_LEDA_ColorCmd.Value
              OUT_VeVTLR_e_PP_LEDB_ColorCmd_Value: accessed-variable=VeVTLR_e_PP_LEDB_ColorCmd.Value
              OUT_VeVTLR_e_PP2_LEDA_ColorCmd_Value: accessed-variable=VeVTLR_e_PP2_LEDA_ColorCmd.Value
              OUT_VeVTLR_e_PP2_LEDB_ColorCmd_Value: accessed-variable=VeVTLR_e_PP2_LEDB_ColorCmd.Value
              OUT_VeVTLR_e_PP_LEDC_Cmd_Value: accessed-variable=VeVTLR_e_PP_LEDC_Cmd.Value
              OUT_VeVTLR_e_PP_LEDC_ColorCmd_Value: accessed-variable=VeVTLR_e_PP_LEDC_ColorCmd.Value
              OUT_VeVTLR_U_MaxACVoltAlwdIDCM_Value: accessed-variable=VeVTLR_U_MaxACVoltAlwdIDCM.Value
              OUT_VeVTLR_I_MaxACCurrAlwdIDCM_Value: accessed-variable=VeVTLR_I_MaxACCurrAlwdIDCM.Value
              OUT_VeVTLR_b_ACFreqCmd_Value: accessed-variable=VeVTLR_b_ACFreqCmd.Value
              OUT_VeVTLR_b_PP_LEDA_ColorCmd_FA_Value: accessed-variable=VeVTLR_b_PP_LEDA_ColorCmd_FA.Value
              OUT_VeVTLR_b_PP_LEDB_ColorCmd_FA_Value: accessed-variable=VeVTLR_b_PP_LEDB_ColorCmd_FA.Value
              OUT_VeVTLR_b_PP_LEDC_Cmd_FA_Value: accessed-variable=VeVTLR_b_PP_LEDC_Cmd_FA.Value
              OUT_VeVTLR_b_PP_LEDC_ColorCmd_FA_Value: accessed-variable=VeVTLR_b_PP_LEDC_ColorCmd_FA.Value
              OUT_VeVTLR_b_PP2_LEDA_ColorCmd_FA_Value: accessed-variable=VeVTLR_b_PP2_LEDA_ColorCmd_FA.Value
              OUT_VeVTLR_b_PP2_LEDB_ColorCmd_FA_Value: accessed-variable=VeVTLR_b_PP2_LEDB_ColorCmd_FA.Value
        VTLR_MedTED: variation-point={short-label=vpVTLR_MedTED, sw-syscond=1}
          data-receive-point-by-arguments:
            71 x access:
              IN_VeBPCR_Pct_HV_BatPackSOC_Arb_Value: accessed-variable=VeBPCR_Pct_HV_BatPackSOC_Arb.Value, variation-point={short-label=vpIN_VeBPCR_Pct_HV_BatPackSOC_Arb_Value, sw-syscond=1}
              IN_VeBPCR_e_HV_BatCntctrStat_Value: accessed-variable=VeBPCR_e_HV_BatCntctrStat.Value, variation-point={short-label=vpIN_VeBPCR_e_HV_BatCntctrStat_Value, sw-syscond=1}
              IN_VeCITR_I_PP2CurrentDrawSens1_Value: accessed-variable=VeCITR_I_PP2CurrentDrawSens1.Value, variation-point={short-label=vpIN_VeCITR_I_PP2CurrentDrawSens1_Value, sw-syscond=1}
              IN_VeCITR_I_PP2CurrentDrawSens2_Value: accessed-variable=VeCITR_I_PP2CurrentDrawSens2.Value, variation-point={short-label=vpIN_VeCITR_I_PP2CurrentDrawSens2_Value, sw-syscond=1}
              IN_VeCITR_I_PPCurrentDrawSens1_Value: accessed-variable=VeCITR_I_PPCurrentDrawSens1.Value, variation-point={short-label=vpIN_VeCITR_I_PPCurrentDrawSens1_Value, sw-syscond=1}
              IN_VeCITR_I_PPCurrentDrawSens2_Value: accessed-variable=VeCITR_I_PPCurrentDrawSens2.Value, variation-point={short-label=vpIN_VeCITR_I_PPCurrentDrawSens2_Value, sw-syscond=1}
              IN_VeCITR_P_PP2RatedPower_Value: accessed-variable=VeCITR_P_PP2RatedPower.Value, variation-point={short-label=vpIN_VeCITR_P_PP2RatedPower_Value, sw-syscond=1}
              IN_VeCITR_P_PPRatedPower_Value: accessed-variable=VeCITR_P_PPRatedPower.Value, variation-point={short-label=vpIN_VeCITR_P_PPRatedPower_Value, sw-syscond=1}
              IN_VeCITR_b_DoorLockLastElSts_Rcvd_Value: accessed-variable=VeCITR_b_DoorLockLastElSts_Rcvd.Value, variation-point={short-label=vpIN_VeCITR_b_DoorLockLastElSts_Rcvd_Value, sw-syscond=1}
              IN_VeCITR_b_Drv_Dr_Unlocking_Value: accessed-variable=VeCITR_b_Drv_Dr_Unlocking.Value, variation-point={short-label=vpIN_VeCITR_b_Drv_Dr_Unlocking_Value, sw-syscond=1}
              IN_VeCITR_b_PP2ACPresentSens1_Value: accessed-variable=VeCITR_b_PP2ACPresentSens1.Value, variation-point={short-label=vpIN_VeCITR_b_PP2ACPresentSens1_Value, sw-syscond=1}
              IN_VeCITR_b_PP2ACPresentSens2_Value: accessed-variable=VeCITR_b_PP2ACPresentSens2.Value, variation-point={short-label=vpIN_VeCITR_b_PP2ACPresentSens2_Value, sw-syscond=1}
              IN_VeCITR_b_PP2ButtonSts_Value: accessed-variable=VeCITR_b_PP2ButtonSts.Value, variation-point={short-label=vpIN_VeCITR_b_PP2ButtonSts_Value, sw-syscond=1}
              IN_VeCITR_b_PP2LidSwitchSts120A_Value: accessed-variable=VeCITR_b_PP2LidSwitchSts120A.Value, variation-point={short-label=vpIN_VeCITR_b_PP2LidSwitchSts120A_Value, sw-syscond=1}
              IN_VeCITR_b_PP2LidSwitchSts120B_Value: accessed-variable=VeCITR_b_PP2LidSwitchSts120B.Value, variation-point={short-label=vpIN_VeCITR_b_PP2LidSwitchSts120B_Value, sw-syscond=1}
              IN_VeCITR_b_PP2LidSwitchSts240_Value: accessed-variable=VeCITR_b_PP2LidSwitchSts240.Value, variation-point={short-label=vpIN_VeCITR_b_PP2LidSwitchSts240_Value, sw-syscond=1}
              IN_VeCITR_b_PPACPresentSens1_Value: accessed-variable=VeCITR_b_PPACPresentSens1.Value, variation-point={short-label=vpIN_VeCITR_b_PPACPresentSens1_Value, sw-syscond=1}
              IN_VeCITR_b_PPACPresentSens2_Value: accessed-variable=VeCITR_b_PPACPresentSens2.Value, variation-point={short-label=vpIN_VeCITR_b_PPACPresentSens2_Value, sw-syscond=1}
              IN_VeCITR_b_PPButtonSts_Value: accessed-variable=VeCITR_b_PPButtonSts.Value, variation-point={short-label=vpIN_VeCITR_b_PPButtonSts_Value, sw-syscond=1}
              IN_VeCITR_b_PPLidSwitchSts120A_Value: accessed-variable=VeCITR_b_PPLidSwitchSts120A.Value, variation-point={short-label=vpIN_VeCITR_b_PPLidSwitchSts120A_Value, sw-syscond=1}
              IN_VeCITR_b_PPLidSwitchSts120B_Value: accessed-variable=VeCITR_b_PPLidSwitchSts120B.Value, variation-point={short-label=vpIN_VeCITR_b_PPLidSwitchSts120B_Value, sw-syscond=1}
              IN_VeCITR_b_PPLidSwitchSts240_Value: accessed-variable=VeCITR_b_PPLidSwitchSts240.Value, variation-point={short-label=vpIN_VeCITR_b_PPLidSwitchSts240_Value, sw-syscond=1}
              IN_VeCITR_b_V2LSubmit_Value: accessed-variable=VeCITR_b_V2LSubmit.Value, variation-point={short-label=vpIN_VeCITR_b_V2LSubmit_Value, sw-syscond=1}
              IN_VeCITR_b_V2LTrunkReq_Value: accessed-variable=VeCITR_b_V2LTrunkReq.Value, variation-point={short-label=vpIN_VeCITR_b_V2LTrunkReq_Value, sw-syscond=1}
              IN_VeCITR_b_V2L_AllReq_Value: accessed-variable=VeCITR_b_V2L_AllReq.Value, variation-point={short-label=vpIN_VeCITR_b_V2L_AllReq_Value, sw-syscond=1}
              IN_VeCITR_b_V2L_FrunkReq_Value: accessed-variable=VeCITR_b_V2L_FrunkReq.Value, variation-point={short-label=vpIN_VeCITR_b_V2L_FrunkReq_Value, sw-syscond=1}
              IN_VeCITR_e_DoorLockLastElSts_Value: accessed-variable=VeCITR_e_DoorLockLastElSts.Value, variation-point={short-label=vpIN_VeCITR_e_DoorLockLastElSts_Value, sw-syscond=1}
              IN_VeCITR_e_FOTA_Install_Status_Value: accessed-variable=VeCITR_e_FOTA_Install_Status.Value, variation-point={short-label=vpIN_VeCITR_e_FOTA_Install_Status_Value, sw-syscond=1}
              IN_VeCITR_e_FOTA_Install_Type_Value: accessed-variable=VeCITR_e_FOTA_Install_Type.Value, variation-point={short-label=vpIN_VeCITR_e_FOTA_Install_Type_Value, sw-syscond=1}
              IN_VeCITR_e_PP2Fault_Value: accessed-variable=VeCITR_e_PP2Fault.Value, variation-point={short-label=vpIN_VeCITR_e_PP2Fault_Value, sw-syscond=1}
              IN_VeCITR_e_PPFault_Value: accessed-variable=VeCITR_e_PPFault.Value, variation-point={short-label=vpIN_VeCITR_e_PPFault_Value, sw-syscond=1}
              IN_VeCSVR_b_VehSpdFA_Value: accessed-variable=VeCSVR_b_VehSpdFA.Value, variation-point={short-label=vpIN_VeCSVR_b_VehSpdFA_Value, sw-syscond=1}
              IN_VeCSVR_v_VehSpdSigned_Value: accessed-variable=VeCSVR_v_VehSpdSigned.Value, variation-point={short-label=vpIN_VeCSVR_v_VehSpdSigned_Value, sw-syscond=1}
              IN_VeDMDR_e_DrvMdArb_Value: accessed-variable=VeDMDR_e_DrvMdArb.Value, variation-point={short-label=vpIN_VeDMDR_e_DrvMdArb_Value, sw-syscond=1}
              IN_VeDMDR_e_TurtleMdSts_Value: accessed-variable=VeDMDR_e_TurtleMdSts.Value, variation-point={short-label=vpIN_VeDMDR_e_TurtleMdSts_Value, sw-syscond=1}
              IN_VeERER_E_WhRemaining_V2L_Value: accessed-variable=VeERER_E_WhRemaining_V2L.Value, variation-point={short-label=vpIN_VeERER_E_WhRemaining_V2L_Value, sw-syscond=1}
              IN_VeESMR_P_BattLTMaxLim_Value: accessed-variable=VeESMR_P_BattLTMaxLim.Value, variation-point={short-label=vpIN_VeESMR_P_BattLTMaxLim_Value, sw-syscond=1}
              IN_VeFSCR_b_HVFuncRejHdAjar_Value: accessed-variable=VeFSCR_b_HVFuncRejHdAjar.Value, variation-point={short-label=vpIN_VeFSCR_b_HVFuncRejHdAjar_Value, sw-syscond=1}
              IN_VeGENR_b_LV_SysVoltage_Low_Value: accessed-variable=VeGENR_b_LV_SysVoltage_Low.Value, variation-point={short-label=vpIN_VeGENR_b_LV_SysVoltage_Low_Value, sw-syscond=1}
              IN_VeHPMR_b_BattCntctrOpenPndg_Value: accessed-variable=VeHPMR_b_BattCntctrOpenPndg.Value, variation-point={short-label=vpIN_VeHPMR_b_BattCntctrOpenPndg_Value, sw-syscond=1}
              IN_VeHPMR_b_CntrlrPwrHold_Value: accessed-variable=VeHPMR_b_CntrlrPwrHold.Value, variation-point={short-label=vpIN_VeHPMR_b_CntrlrPwrHold_Value, sw-syscond=1}
              IN_VeHPMR_b_PropSysActv_Value: accessed-variable=VeHPMR_b_PropSysActv.Value, variation-point={short-label=vpIN_VeHPMR_b_PropSysActv_Value, sw-syscond=1}
              IN_VeHVTR_P_HV_AccPwr_Value: accessed-variable=VeHVTR_P_HV_AccPwr.Value, variation-point={short-label=vpIN_VeHVTR_P_HV_AccPwr_Value, sw-syscond=1}
              IN_VeIDCR_I_BattSide_Curr_Value: accessed-variable=VeIDCR_I_BattSide_Curr.Value, variation-point={short-label=vpIN_VeIDCR_I_BattSide_Curr_Value, sw-syscond=1}
              IN_VeIDCR_I_DCInputCurrent_Value: accessed-variable=VeIDCR_I_DCInputCurrent.Value, variation-point={short-label=vpIN_VeIDCR_I_DCInputCurrent_Value, sw-syscond=1}
              IN_VeIDCR_I_V2X_InputCurrent_Value: accessed-variable=VeIDCR_I_V2X_InputCurrent.Value, variation-point={short-label=vpIN_VeIDCR_I_V2X_InputCurrent_Value, sw-syscond=1}
              IN_VeIDCR_U_ACOutVoltage1_Value: accessed-variable=VeIDCR_U_ACOutVoltage1.Value, variation-point={short-label=vpIN_VeIDCR_U_ACOutVoltage1_Value, sw-syscond=1}
              IN_VeIDCR_U_BattSideVolt_Value: accessed-variable=VeIDCR_U_BattSideVolt.Value, variation-point={short-label=vpIN_VeIDCR_U_BattSideVolt_Value, sw-syscond=1}
              IN_VeIDCR_U_DCInputVoltage_Value: accessed-variable=VeIDCR_U_DCInputVoltage.Value, variation-point={short-label=vpIN_VeIDCR_U_DCInputVoltage_Value, sw-syscond=1}
              IN_VeIDCR_U_V2X_InputVoltage_Value: accessed-variable=VeIDCR_U_V2X_InputVoltage.Value, variation-point={short-label=vpIN_VeIDCR_U_V2X_InputVoltage_Value, sw-syscond=1}
              IN_VeIDCR_b_J1772_S2_Status_Value: accessed-variable=VeIDCR_b_J1772_S2_Status.Value, variation-point={short-label=vpIN_VeIDCR_b_J1772_S2_Status_Value, sw-syscond=1}
              IN_VeIDCR_b_V2X_FailSts_Value: accessed-variable=VeIDCR_b_V2X_FailSts.Value, variation-point={short-label=vpIN_VeIDCR_b_V2X_FailSts_Value, sw-syscond=1}
              IN_VeIDCR_e_ChrgrModeStat_OBCM_Value: accessed-variable=VeIDCR_e_ChrgrModeStat_OBCM.Value, variation-point={short-label=vpIN_VeIDCR_e_ChrgrModeStat_OBCM_Value, sw-syscond=1}
              IN_VeIDCR_e_DschrgFaultSts_Value: accessed-variable=VeIDCR_e_DschrgFaultSts.Value, variation-point={short-label=vpIN_VeIDCR_e_DschrgFaultSts_Value, sw-syscond=1}
              IN_VeIDCR_e_EVSE_PilotStat_OBCM_Value: accessed-variable=VeIDCR_e_EVSE_PilotStat_OBCM.Value, variation-point={short-label=vpIN_VeIDCR_e_EVSE_PilotStat_OBCM_Value, sw-syscond=1}
              IN_VeIDCR_e_ProxStat_Value: accessed-variable=VeIDCR_e_ProxStat.Value, variation-point={short-label=vpIN_VeIDCR_e_ProxStat_Value, sw-syscond=1}
              IN_VeIDCR_e_V2X_ModeFeedback_Value: accessed-variable=VeIDCR_e_V2X_ModeFeedback.Value, variation-point={short-label=vpIN_VeIDCR_e_V2X_ModeFeedback_Value, sw-syscond=1}
              IN_VeOBCR_b_BPCM_Rdy_Value: accessed-variable=VeOBCR_b_BPCM_Rdy.Value, variation-point={short-label=vpIN_VeOBCR_b_BPCM_Rdy_Value, sw-syscond=1}
              IN_VeOBCR_b_EnablePowerTransfer_Value: accessed-variable=VeOBCR_b_EnablePowerTransfer.Value, variation-point={short-label=vpIN_VeOBCR_b_EnablePowerTransfer_Value, sw-syscond=1}
              IN_VeOBCR_b_PluggedIn_Value: accessed-variable=VeOBCR_b_PluggedIn.Value, variation-point={short-label=vpIN_VeOBCR_b_PluggedIn_Value, sw-syscond=1}
              IN_VeOBCR_b_SecureConnV2L_Value: accessed-variable=VeOBCR_b_SecureConnV2L.Value, variation-point={short-label=vpIN_VeOBCR_b_SecureConnV2L_Value, sw-syscond=1}
              IN_VePLTR_b_InternalLightSts_Value: accessed-variable=VePLTR_b_InternalLightSts.Value, variation-point={short-label=vpIN_VePLTR_b_InternalLightSts_Value, sw-syscond=1}
              IN_VePLTR_b_RmtVehStartReq_Value: accessed-variable=VePLTR_b_RmtVehStartReq.Value, variation-point={short-label=vpIN_VePLTR_b_RmtVehStartReq_Value, sw-syscond=1}
              IN_VePLTR_t_RTC_CurrentTime_Value: accessed-variable=VePLTR_t_RTC_CurrentTime.Value, variation-point={short-label=vpIN_VePLTR_t_RTC_CurrentTime_Value, sw-syscond=1}
              IN_VePMDR_e_PMM_PowerMode_Value: accessed-variable=VePMDR_e_PMM_PowerMode.Value, variation-point={short-label=vpIN_VePMDR_e_PMM_PowerMode_Value, sw-syscond=1}
              IN_VeSRAR_b_StpCharging_Value: accessed-variable=VeSRAR_b_StpCharging.Value, variation-point={short-label=vpIN_VeSRAR_b_StpCharging_Value, sw-syscond=1}
              IN_VeSSDR_b_DsblHVBattDischrg_Value: accessed-variable=VeSSDR_b_DsblHVBattDischrg.Value, variation-point={short-label=vpIN_VeSSDR_b_DsblHVBattDischrg_Value, sw-syscond=1}
              IN_VeTRGR_e_VldtdTransRngSt_Value: accessed-variable=VeTRGR_e_VldtdTransRngSt.Value, variation-point={short-label=vpIN_VeTRGR_e_VldtdTransRngSt_Value, sw-syscond=1}
              IN_VeVDVR_I_DschrgCrntLmt_Value: accessed-variable=VeVDVR_I_DschrgCrntLmt.Value, variation-point={short-label=vpIN_VeVDVR_I_DschrgCrntLmt_Value, sw-syscond=1}
              IN_VeVDVR_e_DschrgSysSts_Value: accessed-variable=VeVDVR_e_DschrgSysSts.Value, variation-point={short-label=vpIN_VeVDVR_e_DschrgSysSts_Value, sw-syscond=1}
              IN_VeVTXR_e_PowerPanelMd_Value: accessed-variable=VeVTXR_e_PowerPanelMd.Value, variation-point={short-label=vpIN_VeVTXR_e_PowerPanelMd_Value, sw-syscond=1}
          data-send-points:
            49 x access:
              OUT_VeVTLR_b_V2LPlugIn_Auth_Value: accessed-variable=VeVTLR_b_V2LPlugIn_Auth.Value
              OUT_VeVTLR_I_DschrgCrntLmt_Value: accessed-variable=VeVTLR_I_DschrgCrntLmt.Value
              OUT_VeVTLR_e_DschrgOBCMdRq_Value: accessed-variable=VeVTLR_e_DschrgOBCMdRq.Value
              OUT_VeVTLR_b_DschrgS2Cmd_Value: accessed-variable=VeVTLR_b_DschrgS2Cmd.Value
              OUT_VeVTLR_b_DschrgUnlckInlet_Value: accessed-variable=VeVTLR_b_DschrgUnlckInlet.Value
              OUT_VeVTLR_b_EnableDischarge_Value: accessed-variable=VeVTLR_b_EnableDischarge.Value
              OUT_VeVTLR_b_Trunk_Auth_Value: accessed-variable=VeVTLR_b_Trunk_Auth.Value
              OUT_VeVTLR_b_Frunk_Auth_Value: accessed-variable=VeVTLR_b_Frunk_Auth.Value
              OUT_VeVTLR_e_DschrgOBCMdRq_Onboard_Value: accessed-variable=VeVTLR_e_DschrgOBCMdRq_Onboard.Value
              OUT_VeVTLR_b_ACSw_Cmd_Value: accessed-variable=VeVTLR_b_ACSw_Cmd.Value
              OUT_VeVTLR_e_TrunkSts_Value: accessed-variable=VeVTLR_e_TrunkSts.Value
              OUT_VeVTLR_e_PP1_LEDA_Cmd_Value: accessed-variable=VeVTLR_e_PP1_LEDA_Cmd.Value
              OUT_VeVTLR_e_PP1_LEDB_Cmd_Value: accessed-variable=VeVTLR_e_PP1_LEDB_Cmd.Value
              OUT_VeVTLR_e_PPIM_MdRq_Value: accessed-variable=VeVTLR_e_PPIM_MdRq.Value
              OUT_VeVTLR_b_Rdy4ShtDwn_Value: accessed-variable=VeVTLR_b_Rdy4ShtDwn.Value
              OUT_VeVTLR_e_FrunkSts_Value: accessed-variable=VeVTLR_e_FrunkSts.Value
              OUT_VeVTLR_e_PP2_LEDA_Cmd_Value: accessed-variable=VeVTLR_e_PP2_LEDA_Cmd.Value
              OUT_VeVTLR_e_PP2_LEDB_Cmd_Value: accessed-variable=VeVTLR_e_PP2_LEDB_Cmd.Value
              OUT_VeVTLR_P_InstantPwr_IDCM_Value: accessed-variable=VeVTLR_P_InstantPwr_IDCM.Value
              OUT_VeVTLR_P_InstantPwr_PPIM_Value: accessed-variable=VeVTLR_P_InstantPwr_PPIM.Value
              OUT_VeVTLR_I_MaxCurrAlwd_PPIM_Value: accessed-variable=VeVTLR_I_MaxCurrAlwd_PPIM.Value
              OUT_VeVTLR_b_PP1_DayLightMd_Value: accessed-variable=VeVTLR_b_PP1_DayLightMd.Value
              OUT_VeVTLR_b_PP2_DayLightMd_Value: accessed-variable=VeVTLR_b_PP2_DayLightMd.Value
              OUT_VeVTLR_t_DschrgDays_Value: accessed-variable=VeVTLR_t_DschrgDays.Value
              OUT_VeVTLR_t_DschrgHrs_Value: accessed-variable=VeVTLR_t_DschrgHrs.Value
              OUT_VeVTLR_t_DschrgMins_Value: accessed-variable=VeVTLR_t_DschrgMins.Value
              OUT_VeVTLR_b_OnboardPP1_Dtctd_Value: accessed-variable=VeVTLR_b_OnboardPP1_Dtctd.Value
              OUT_VeVTLR_b_OnboardPP2_Dtctd_Value: accessed-variable=VeVTLR_b_OnboardPP2_Dtctd.Value
              OUT_VeVTLR_b_Rdy4ShtDwn_OnboardPP1_Value: accessed-variable=VeVTLR_b_Rdy4ShtDwn_OnboardPP1.Value
              OUT_VeVTLR_b_Rdy4ShtDwn_OnboardPP2_Value: accessed-variable=VeVTLR_b_Rdy4ShtDwn_OnboardPP2.Value
              OUT_VeVTLR_b_ACSwSts_Value: accessed-variable=VeVTLR_b_ACSwSts.Value
              OUT_VeVTLR_I_MaxCurrAlwd_IDCM_Value: accessed-variable=VeVTLR_I_MaxCurrAlwd_IDCM.Value
              OUT_VeVTLR_e_DschrgSysSts_Value: accessed-variable=VeVTLR_e_DschrgSysSts.Value
              OUT_VeVTLR_Pct_V2L_OB_RsrvBatt_Value: accessed-variable=VeVTLR_Pct_V2L_OB_RsrvBatt.Value
              OUT_VeVTLR_e_PP_LEDA_ColorCmd_Value: accessed-variable=VeVTLR_e_PP_LEDA_ColorCmd.Value
              OUT_VeVTLR_e_PP_LEDB_ColorCmd_Value: accessed-variable=VeVTLR_e_PP_LEDB_ColorCmd.Value
              OUT_VeVTLR_e_PP2_LEDA_ColorCmd_Value: accessed-variable=VeVTLR_e_PP2_LEDA_ColorCmd.Value
              OUT_VeVTLR_e_PP2_LEDB_ColorCmd_Value: accessed-variable=VeVTLR_e_PP2_LEDB_ColorCmd.Value
              OUT_VeVTLR_e_PP_LEDC_Cmd_Value: accessed-variable=VeVTLR_e_PP_LEDC_Cmd.Value
              OUT_VeVTLR_e_PP_LEDC_ColorCmd_Value: accessed-variable=VeVTLR_e_PP_LEDC_ColorCmd.Value
              OUT_VeVTLR_U_MaxACVoltAlwdIDCM_Value: accessed-variable=VeVTLR_U_MaxACVoltAlwdIDCM.Value
              OUT_VeVTLR_I_MaxACCurrAlwdIDCM_Value: accessed-variable=VeVTLR_I_MaxACCurrAlwdIDCM.Value
              OUT_VeVTLR_b_ACFreqCmd_Value: accessed-variable=VeVTLR_b_ACFreqCmd.Value
              OUT_VeVTLR_b_PP_LEDA_ColorCmd_FA_Value: accessed-variable=VeVTLR_b_PP_LEDA_ColorCmd_FA.Value
              OUT_VeVTLR_b_PP_LEDB_ColorCmd_FA_Value: accessed-variable=VeVTLR_b_PP_LEDB_ColorCmd_FA.Value
              OUT_VeVTLR_b_PP_LEDC_ColorCmd_FA_Value: accessed-variable=VeVTLR_b_PP_LEDC_ColorCmd_FA.Value
              OUT_VeVTLR_b_PP2_LEDA_ColorCmd_FA_Value: accessed-variable=VeVTLR_b_PP2_LEDA_ColorCmd_FA.Value
              OUT_VeVTLR_b_PP2_LEDB_ColorCmd_FA_Value: accessed-variable=VeVTLR_b_PP2_LEDB_ColorCmd_FA.Value
              OUT_VeVTLR_b_PP_LEDC_Cmd_FA_Value: accessed-variable=VeVTLR_b_PP_LEDC_Cmd_FA.Value
        VTLR_PwrOff: variation-point={short-label=vpVTLR_PwrOff, sw-syscond=1}
          data-send-points:
            5 x access:
              OUT_EeVTLR_b_V2L_PlugInAuth_EeVTLR_b_V2L_PlugInAuth: accessed-variable=EeVTLR_b_V2L_PlugInAuth.EeVTLR_b_V2L_PlugInAuth, variation-point={short-label=vpOUT_EeVTLR_b_V2L_PlugInAuth_EeVTLR_b_V2L_PlugInAuth, sw-syscond=1}
              OUT_EeVTLR_Cnt_AuthTmr_EeVTLR_Cnt_AuthTmr: accessed-variable=EeVTLR_Cnt_AuthTmr.EeVTLR_Cnt_AuthTmr, variation-point={short-label=vpOUT_EeVTLR_Cnt_AuthTmr_EeVTLR_Cnt_AuthTmr, sw-syscond=1}
              OUT_NeVTLR_e_DoorLastSts_NeVTLR_e_DoorLastSts: accessed-variable=NeVTLR_e_DoorLastSts.NeVTLR_e_DoorLastSts, variation-point={short-label=vpOUT_NeVTLR_e_DoorLastSts_NeVTLR_e_DoorLastSts, sw-syscond=1}
              OUT_EeVTLR_b_V2L_OB_IDCM_Auth_EeVTLR_b_V2L_OB_IDCM_Auth: accessed-variable=EeVTLR_b_V2L_OB_IDCM_Auth.EeVTLR_b_V2L_OB_IDCM_Auth, variation-point={short-label=vpOUT_EeVTLR_b_V2L_OB_IDCM_Auth_EeVTLR_b_V2L_OB_IDCM_Auth, sw-syscond=1}
              OUT_EeVTLR_b_V2L_OB_PPIM_Auth_EeVTLR_b_V2L_OB_PPIM_Auth: accessed-variable=EeVTLR_b_V2L_OB_PPIM_Auth.EeVTLR_b_V2L_OB_PPIM_Auth, variation-point={short-label=vpOUT_EeVTLR_b_V2L_OB_PPIM_Auth_EeVTLR_b_V2L_OB_PPIM_Auth, sw-syscond=1}
      variation point proxy Variant_VTLR_1: category=CONDITION, condition-access=1
